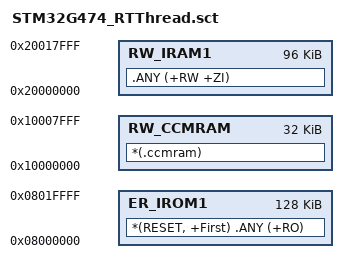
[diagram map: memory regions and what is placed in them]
/* STM32G474RBT3: 128 KiB Flash, 96 KiB main SRAM, 32 KiB CCM SRAM.
 * DMA-visible objects stay in RW_IRAM1. CPU-only RT stacks and the event log
 * use the explicit .ccmram region at 0x10000000. */
LR_IROM1 0x08000000 0x00020000
{
  ER_IROM1 0x08000000 0x00020000 { *(RESET, +First) .ANY (+RO) }
  RW_CCMRAM 0x10000000 0x00008000 { *(.ccmram) }
  RW_IRAM1 0x20000000 0x00018000 { .ANY (+RW +ZI) }
}
